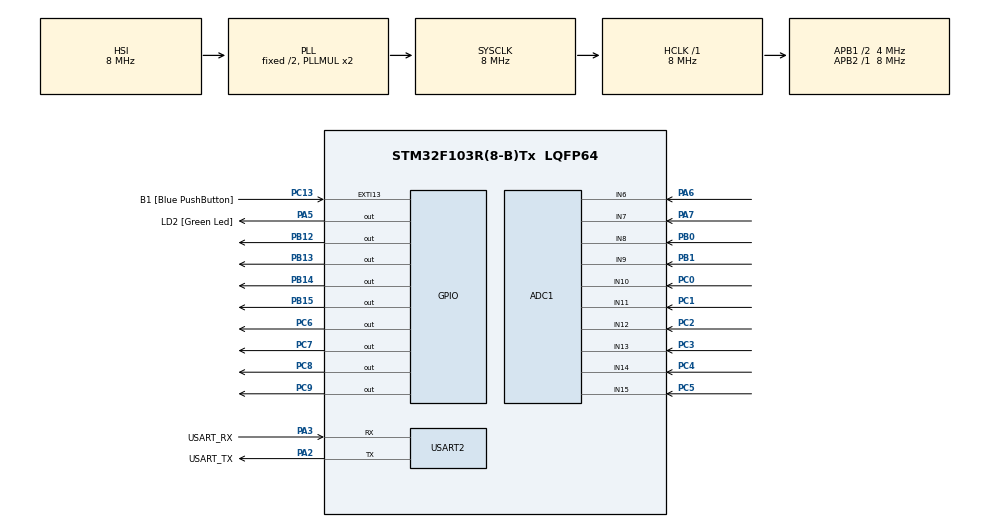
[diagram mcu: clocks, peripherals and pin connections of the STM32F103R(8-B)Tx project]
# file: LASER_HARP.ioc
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ADC1.Channel-10\#ChannelRegularConversion=ADC_CHANNEL_10
ADC1.Channel-11\#ChannelRegularConversion=ADC_CHANNEL_11
ADC1.Channel-12\#ChannelRegularConversion=ADC_CHANNEL_12
ADC1.Channel-13\#ChannelRegularConversion=ADC_CHANNEL_13
ADC1.Channel-14\#ChannelRegularConversion=ADC_CHANNEL_14
ADC1.Channel-15\#ChannelRegularConversion=ADC_CHANNEL_15
ADC1.Channel-6\#ChannelRegularConversion=ADC_CHANNEL_6
ADC1.Channel-7\#ChannelRegularConversion=ADC_CHANNEL_7
ADC1.Channel-8\#ChannelRegularConversion=ADC_CHANNEL_8
ADC1.Channel-9\#ChannelRegularConversion=ADC_CHANNEL_9
ADC1.ContinuousConvMode=ENABLE
ADC1.NbrOfConversion=10
ADC1.NbrOfConversionFlag=1
ADC1.Rank-10\#ChannelRegularConversion=5
ADC1.Rank-11\#ChannelRegularConversion=6
ADC1.Rank-12\#ChannelRegularConversion=7
ADC1.Rank-13\#ChannelRegularConversion=8
ADC1.Rank-14\#ChannelRegularConversion=9
ADC1.Rank-15\#ChannelRegularConversion=10
ADC1.Rank-6\#ChannelRegularConversion=1
ADC1.Rank-7\#ChannelRegularConversion=2
ADC1.Rank-8\#ChannelRegularConversion=3
ADC1.Rank-9\#ChannelRegularConversion=4
ADC1.SamplingTime-10\#ChannelRegularConversion=ADC_SAMPLETIME_239CYCLES_5
ADC1.SamplingTime-11\#ChannelRegularConversion=ADC_SAMPLETIME_239CYCLES_5
ADC1.SamplingTime-12\#ChannelRegularConversion=ADC_SAMPLETIME_239CYCLES_5
ADC1.SamplingTime-13\#ChannelRegularConversion=ADC_SAMPLETIME_239CYCLES_5
ADC1.SamplingTime-14\#ChannelRegularConversion=ADC_SAMPLETIME_239CYCLES_5
ADC1.SamplingTime-15\#ChannelRegularConversion=ADC_SAMPLETIME_239CYCLES_5
ADC1.SamplingTime-6\#ChannelRegularConversion=ADC_SAMPLETIME_1CYCLE_5
ADC1.SamplingTime-7\#ChannelRegularConversion=ADC_SAMPLETIME_239CYCLES_5
ADC1.SamplingTime-8\#ChannelRegularConversion=ADC_SAMPLETIME_239CYCLES_5
ADC1.SamplingTime-9\#ChannelRegularConversion=ADC_SAMPLETIME_239CYCLES_5
ADC1.master=1
Dma.ADC1.0.Direction=DMA_PERIPH_TO_MEMORY
Dma.ADC1.0.Instance=DMA1_Channel1
Dma.ADC1.0.MemDataAlignment=DMA_MDATAALIGN_HALFWORD
Dma.ADC1.0.MemInc=DMA_MINC_ENABLE
Dma.ADC1.0.Mode=DMA_CIRCULAR
Dma.ADC1.0.PeriphDataAlignment=DMA_PDATAALIGN_HALFWORD
Dma.ADC1.0.PeriphInc=DMA_PINC_DISABLE
Dma.ADC1.0.Priority=DMA_PRIORITY_LOW
Dma.Request0=ADC1
Mcu.Family=STM32F1
Mcu.Name=STM32F103R(8-B)Tx
Mcu.Package=LQFP64
NVIC.DMA1_Channel1_IRQn=true\:0\:0\:false\:false\:true\:false\:true
NVIC.EXTI15_10_IRQn=true\:0\:0\:false\:false\:true\:true\:true
NVIC.PriorityGroup=NVIC_PRIORITYGROUP_4
PA13.GPIO_Label=TMS
PA13.Mode=Serial_Wire
PA13.Signal=SYS_JTMS-SWDIO
PA14.GPIO_Label=TCK
PA14.Mode=Serial_Wire
PA14.Signal=SYS_JTCK-SWCLK
PA2.GPIO_Label=USART_TX
PA2.GPIO_Mode=GPIO_MODE_AF_PP
PA2.GPIO_PuPd=GPIO_NOPULL
PA2.GPIO_Speed=GPIO_SPEED_FREQ_LOW
PA2.Mode=Asynchronous
PA2.Signal=USART2_TX
PA3.GPIO_Label=USART_RX
PA3.GPIO_Mode=GPIO_MODE_AF_PP
PA3.GPIO_PuPd=GPIO_NOPULL
PA3.GPIO_Speed=GPIO_SPEED_FREQ_LOW
PA3.Mode=Asynchronous
PA3.Signal=USART2_RX
PA5.GPIO_Label=LD2 [Green Led]
PA5.GPIO_ModeDefaultOutputPP=GPIO_MODE_OUTPUT_PP
PA5.GPIO_PuPd=GPIO_NOPULL
PA5.GPIO_Speed=GPIO_SPEED_FREQ_LOW
PA5.Signal=GPIO_Output
PA6.Signal=ADCx_IN6
PA7.Signal=ADCx_IN7
PB0.Signal=ADCx_IN8
PB1.Signal=ADCx_IN9
PB12.PinState=GPIO_PIN_SET
PB12.Signal=GPIO_Output
PB13.PinState=GPIO_PIN_SET
PB13.Signal=GPIO_Output
PB14.PinState=GPIO_PIN_SET
PB14.Signal=GPIO_Output
PB15.PinState=GPIO_PIN_SET
PB15.Signal=GPIO_Output
PB3.GPIO_Label=SWO
PB3.Signal=SYS_JTDO-TRACESWO
PC0.Signal=ADCx_IN10
PC1.Signal=ADCx_IN11
PC13-TAMPER-RTC.GPIO_Label=B1 [Blue PushButton]
PC13-TAMPER-RTC.GPIO_PuPd=GPIO_NOPULL
PC13-TAMPER-RTC.Signal=GPXTI13
PC14-OSC32_IN.Mode=LSE-External-Oscillator
PC14-OSC32_IN.Signal=RCC_OSC32_IN
PC15-OSC32_OUT.Mode=LSE-External-Oscillator
PC15-OSC32_OUT.Signal=RCC_OSC32_OUT
PC2.Signal=ADCx_IN12
PC3.Signal=ADCx_IN13
PC4.Signal=ADCx_IN14
PC5.Signal=ADCx_IN15
PC6.PinState=GPIO_PIN_SET
PC6.Signal=GPIO_Output
PC7.PinState=GPIO_PIN_SET
PC7.Signal=GPIO_Output
PC8.PinState=GPIO_PIN_SET
PC8.Signal=GPIO_Output
PC9.PinState=GPIO_PIN_SET
PC9.Signal=GPIO_Output
PD0-OSC_IN.Mode=HSE-External-Clock-Source
PD0-OSC_IN.Signal=RCC_OSC_IN
PD1-OSC_OUT.Mode=HSE-External-Clock-Source
PD1-OSC_OUT.Signal=RCC_OSC_OUT
ProjectManager.HeapSize=0x200
ProjectManager.StackSize=0x400
ProjectManager.TargetToolchain=STM32CubeIDE
RCC.AHBFreq_Value=8000000
RCC.APB1CLKDivider=RCC_HCLK_DIV2
RCC.APB1Freq_Value=4000000
RCC.APB1TimFreq_Value=8000000
RCC.APB2Freq_Value=8000000
RCC.APB2TimFreq_Value=8000000
RCC.HCLKFreq_Value=8000000
RCC.RTCClockSelection=RCC_RTCCLKSOURCE_LSE
RCC.SYSCLKFreq_VALUE=8000000
RCC.SYSCLKSource=RCC_SYSCLKSOURCE_PLLCLK
RCC.USBFreq_Value=8000000
SH.ADCx_IN10.0=ADC1_IN10,IN10
SH.ADCx_IN11.0=ADC1_IN11,IN11
SH.ADCx_IN12.0=ADC1_IN12,IN12
SH.ADCx_IN13.0=ADC1_IN13,IN13
SH.ADCx_IN14.0=ADC1_IN14,IN14
SH.ADCx_IN15.0=ADC1_IN15,IN15
SH.ADCx_IN6.0=ADC1_IN6,IN6
SH.ADCx_IN7.0=ADC1_IN7,IN7
SH.ADCx_IN8.0=ADC1_IN8,IN8
SH.ADCx_IN9.0=ADC1_IN9,IN9
USART2.VirtualMode=VM_ASYNC
board=NUCLEO-F103RB

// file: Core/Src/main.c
/* USER CODE BEGIN Header */
/**
  ******************************************************************************
  * @file           : main.c
  * @brief          : Main program body
  ******************************************************************************
  * @attention
  *
  * <h2><center>&copy; Copyright (c) 2020 STMicroelectronics.
  * All rights reserved.</center></h2>
  *
  * This software component is licensed by ST under BSD 3-Clause license,
  * the "License"; You may not use this file except in compliance with the
  * License. You may obtain a copy of the License at:
  *                        opensource.org/licenses/BSD-3-Clause
  *
  ******************************************************************************
  */
/* USER CODE END Header */

#include "main.h"

ADC_HandleTypeDef hadc1;
DMA_HandleTypeDef hdma_adc1;

UART_HandleTypeDef huart2;

/* USER CODE BEGIN PV */
// ldr = light-dependent resistor
uint16_t ldr[10]; //contains photoresistors voltage output, there are 10 photoresistors connected to the board
/* USER CODE END PV */

void SystemClock_Config(void);
static void MX_GPIO_Init(void);
static void MX_DMA_Init(void);
static void MX_USART2_UART_Init(void);
static void MX_ADC1_Init(void);

int main(void)
{

  /* MCU Configuration--------------------------------------------------------*/

  /* Reset of all peripherals, Initializes the Flash interface and the Systick. */
  HAL_Init();

  /* Configure the system clock */
  SystemClock_Config();

  /* Initialize all configured peripherals */
  MX_GPIO_Init();
  MX_DMA_Init();
  MX_USART2_UART_Init();
  MX_ADC1_Init();
  /* USER CODE BEGIN 2 */
  HAL_ADC_Start_DMA(&hadc1, ldr, 10);
  /* USER CODE END 2 */

  /* Infinite loop */
  while (1)
  {

  }
}

void SystemClock_Config(void)
{
  RCC_OscInitTypeDef RCC_OscInitStruct = {0};
  RCC_ClkInitTypeDef RCC_ClkInitStruct = {0};
  RCC_PeriphCLKInitTypeDef PeriphClkInit = {0};

  /** Initializes the CPU, AHB and APB busses clocks
  */
  RCC_OscInitStruct.OscillatorType = RCC_OSCILLATORTYPE_HSI;
  RCC_OscInitStruct.HSIState = RCC_HSI_ON;
  RCC_OscInitStruct.HSICalibrationValue = RCC_HSICALIBRATION_DEFAULT;
  RCC_OscInitStruct.PLL.PLLState = RCC_PLL_ON;
  RCC_OscInitStruct.PLL.PLLSource = RCC_PLLSOURCE_HSI_DIV2;
  RCC_OscInitStruct.PLL.PLLMUL = RCC_PLL_MUL2;
  if (HAL_RCC_OscConfig(&RCC_OscInitStruct) != HAL_OK)
  {
    Error_Handler();
  }
  /** Initializes the CPU, AHB and APB busses clocks
  */
  RCC_ClkInitStruct.ClockType = RCC_CLOCKTYPE_HCLK|RCC_CLOCKTYPE_SYSCLK
                              |RCC_CLOCKTYPE_PCLK1|RCC_CLOCKTYPE_PCLK2;
  RCC_ClkInitStruct.SYSCLKSource = RCC_SYSCLKSOURCE_PLLCLK;
  RCC_ClkInitStruct.AHBCLKDivider = RCC_SYSCLK_DIV1;
  RCC_ClkInitStruct.APB1CLKDivider = RCC_HCLK_DIV2;
  RCC_ClkInitStruct.APB2CLKDivider = RCC_HCLK_DIV1;

  if (HAL_RCC_ClockConfig(&RCC_ClkInitStruct, FLASH_LATENCY_0) != HAL_OK)
  {
    Error_Handler();
  }
  PeriphClkInit.PeriphClockSelection = RCC_PERIPHCLK_ADC;
  PeriphClkInit.AdcClockSelection = RCC_ADCPCLK2_DIV2;
  if (HAL_RCCEx_PeriphCLKConfig(&PeriphClkInit) != HAL_OK)
  {
    Error_Handler();
  }
}

static void MX_ADC1_Init(void)
{

  ADC_ChannelConfTypeDef sConfig = {0};

  /** Common config
  */
  hadc1.Instance = ADC1;
  hadc1.Init.ScanConvMode = ADC_SCAN_ENABLE;
  hadc1.Init.ContinuousConvMode = ENABLE;
  hadc1.Init.DiscontinuousConvMode = DISABLE;
  hadc1.Init.ExternalTrigConv = ADC_SOFTWARE_START;
  hadc1.Init.DataAlign = ADC_DATAALIGN_RIGHT;
  hadc1.Init.NbrOfConversion = 10;
  if (HAL_ADC_Init(&hadc1) != HAL_OK)
  {
    Error_Handler();
  }
  /** Configure Regular Channel
  */
  sConfig.Channel = ADC_CHANNEL_6;
  sConfig.Rank = ADC_REGULAR_RANK_1;
  sConfig.SamplingTime = ADC_SAMPLETIME_1CYCLE_5;
  if (HAL_ADC_ConfigChannel(&hadc1, &sConfig) != HAL_OK)
  {
    Error_Handler();
  }
  /** Configure Regular Channel
  */
  sConfig.Channel = ADC_CHANNEL_7;
  sConfig.Rank = ADC_REGULAR_RANK_2;
  sConfig.SamplingTime = ADC_SAMPLETIME_239CYCLES_5;
  if (HAL_ADC_ConfigChannel(&hadc1, &sConfig) != HAL_OK)
  {
    Error_Handler();
  }
  /** Configure Regular Channel
  */
  sConfig.Channel = ADC_CHANNEL_8;
  sConfig.Rank = ADC_REGULAR_RANK_3;
  if (HAL_ADC_ConfigChannel(&hadc1, &sConfig) != HAL_OK)
  {
    Error_Handler();
  }
  /** Configure Regular Channel
  */
  sConfig.Channel = ADC_CHANNEL_9;
  sConfig.Rank = ADC_REGULAR_RANK_4;
  if (HAL_ADC_ConfigChannel(&hadc1, &sConfig) != HAL_OK)
  {
    Error_Handler();
  }
  /** Configure Regular Channel
  */
  sConfig.Channel = ADC_CHANNEL_10;
  sConfig.Rank = ADC_REGULAR_RANK_5;
  if (HAL_ADC_ConfigChannel(&hadc1, &sConfig) != HAL_OK)
  {
    Error_Handler();
  }
  /** Configure Regular Channel
  */
  sConfig.Channel = ADC_CHANNEL_11;
  sConfig.Rank = ADC_REGULAR_RANK_6;
  if (HAL_ADC_ConfigChannel(&hadc1, &sConfig) != HAL_OK)
  {
    Error_Handler();
  }
  /** Configure Regular Channel
  */
  sConfig.Channel = ADC_CHANNEL_12;
  sConfig.Rank = ADC_REGULAR_RANK_7;
  if (HAL_ADC_ConfigChannel(&hadc1, &sConfig) != HAL_OK)
  {
    Error_Handler();
  }
  /** Configure Regular Channel
  */
  sConfig.Channel = ADC_CHANNEL_13;
  sConfig.Rank = ADC_REGULAR_RANK_8;
  if (HAL_ADC_ConfigChannel(&hadc1, &sConfig) != HAL_OK)
  {
    Error_Handler();
  }
  /** Configure Regular Channel
  */
  sConfig.Channel = ADC_CHANNEL_14;
  sConfig.Rank = ADC_REGULAR_RANK_9;
  if (HAL_ADC_ConfigChannel(&hadc1, &sConfig) != HAL_OK)
  {
    Error_Handler();
  }
  /** Configure Regular Channel
  */
  sConfig.Channel = ADC_CHANNEL_15;
  sConfig.Rank = ADC_REGULAR_RANK_10;
  if (HAL_ADC_ConfigChannel(&hadc1, &sConfig) != HAL_OK)
  {
    Error_Handler();
  }

}

static void MX_USART2_UART_Init(void)
{

  huart2.Instance = USART2;
  huart2.Init.BaudRate = 115200;
  huart2.Init.WordLength = UART_WORDLENGTH_8B;
  huart2.Init.StopBits = UART_STOPBITS_1;
  huart2.Init.Parity = UART_PARITY_NONE;
  huart2.Init.Mode = UART_MODE_TX_RX;
  huart2.Init.HwFlowCtl = UART_HWCONTROL_NONE;
  huart2.Init.OverSampling = UART_OVERSAMPLING_16;
  if (HAL_UART_Init(&huart2) != HAL_OK)
  {
    Error_Handler();
  }

}

static void MX_DMA_Init(void)
{

  /* DMA controller clock enable */
  __HAL_RCC_DMA1_CLK_ENABLE();

  /* DMA interrupt init */
  /* DMA1_Channel1_IRQn interrupt configuration */
  HAL_NVIC_SetPriority(DMA1_Channel1_IRQn, 0, 0);
  HAL_NVIC_EnableIRQ(DMA1_Channel1_IRQn);

}

static void MX_GPIO_Init(void)
{
  GPIO_InitTypeDef GPIO_InitStruct = {0};

  /* GPIO Ports Clock Enable */
  __HAL_RCC_GPIOC_CLK_ENABLE();
  __HAL_RCC_GPIOD_CLK_ENABLE();
  __HAL_RCC_GPIOA_CLK_ENABLE();
  __HAL_RCC_GPIOB_CLK_ENABLE();

  /*Configure GPIO pin Output Level */
  HAL_GPIO_WritePin(LD2_GPIO_Port, LD2_Pin, GPIO_PIN_RESET);

  /*Configure GPIO pin Output Level */
  HAL_GPIO_WritePin(GPIOB, GPIO_PIN_12|GPIO_PIN_13|GPIO_PIN_14|GPIO_PIN_15, GPIO_PIN_SET);

  /*Configure GPIO pin Output Level */
  HAL_GPIO_WritePin(GPIOC, GPIO_PIN_6|GPIO_PIN_7|GPIO_PIN_8|GPIO_PIN_9, GPIO_PIN_SET);

  /*Configure GPIO pin : B1_Pin */
  GPIO_InitStruct.Pin = B1_Pin;
  GPIO_InitStruct.Mode = GPIO_MODE_IT_RISING;
  GPIO_InitStruct.Pull = GPIO_NOPULL;
  HAL_GPIO_Init(B1_GPIO_Port, &GPIO_InitStruct);

  /*Configure GPIO pin : LD2_Pin */
  GPIO_InitStruct.Pin = LD2_Pin;
  GPIO_InitStruct.Mode = GPIO_MODE_OUTPUT_PP;
  GPIO_InitStruct.Pull = GPIO_NOPULL;
  GPIO_InitStruct.Speed = GPIO_SPEED_FREQ_LOW;
  HAL_GPIO_Init(LD2_GPIO_Port, &GPIO_InitStruct);

  /*Configure GPIO pins : PB12 PB13 PB14 PB15 */
  GPIO_InitStruct.Pin = GPIO_PIN_12|GPIO_PIN_13|GPIO_PIN_14|GPIO_PIN_15;
  GPIO_InitStruct.Mode = GPIO_MODE_OUTPUT_PP;
  GPIO_InitStruct.Pull = GPIO_NOPULL;
  GPIO_InitStruct.Speed = GPIO_SPEED_FREQ_LOW;
  HAL_GPIO_Init(GPIOB, &GPIO_InitStruct);

  /*Configure GPIO pins : PC6 PC7 PC8 PC9 */
  GPIO_InitStruct.Pin = GPIO_PIN_6|GPIO_PIN_7|GPIO_PIN_8|GPIO_PIN_9;
  GPIO_InitStruct.Mode = GPIO_MODE_OUTPUT_PP;
  GPIO_InitStruct.Pull = GPIO_NOPULL;
  GPIO_InitStruct.Speed = GPIO_SPEED_FREQ_LOW;
  HAL_GPIO_Init(GPIOC, &GPIO_InitStruct);

  /* EXTI interrupt init*/
  HAL_NVIC_SetPriority(EXTI15_10_IRQn, 0, 0);
  HAL_NVIC_EnableIRQ(EXTI15_10_IRQn);

}

void Error_Handler(void)
{
}

/************************ (C) COPYRIGHT STMicroelectronics *****END OF FILE****/
